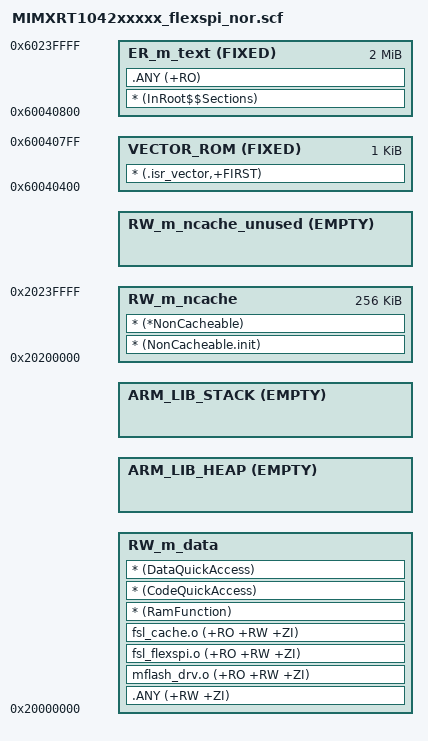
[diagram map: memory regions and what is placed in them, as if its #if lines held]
#!armclang --target=arm-arm-none-eabi -mcpu=cortex-m7 -E -x c
/*
** ###################################################################
**     Processors:          MIMXRT1042DFP6B
**                          MIMXRT1042XFP5B
**                          MIMXRT1042XJM5B
**
**     Compiler:            Keil ARM C/C++ Compiler
**     Reference manual:    IMXRT1040RM Rev.A, 09/2021
**     Version:             rev. 0.1, 2021-07-20
**     Build:               b211221
**
**     Abstract:
**         Linker file for the Keil ARM C/C++ Compiler
**
**     Copyright 2016 Freescale Semiconductor, Inc.
**     Copyright 2016-2021 NXP
**     All rights reserved.
**
**     SPDX-License-Identifier: BSD-3-Clause
**
**     http:                 www.nxp.com
**     mail:                 support@nxp.com
**
** ###################################################################
*/

/* Primary application image is up to 2 MB in size including headers and interrupt vectors */

#define m_interrupts_start             0x60040400
#define m_interrupts_size              0x00000400

#define m_text_start                   0x60040800
#define m_text_size                    0x001FF800

#define m_data_start                   0x20000000
#define m_data_size                    0x00020000

#define m_ncache_start                 0x20200000
#define m_ncache_size                  0x00040000


/* Sizes */
#if (defined(__stack_size__))
  #define Stack_Size                   __stack_size__
#else
  #define Stack_Size                   0x0400
#endif

#if (defined(__heap_size__))
  #define Heap_Size                    __heap_size__
#else
  #define Heap_Size                    0x0400
#endif

LR_m_text m_interrupts_start m_text_start+m_text_size-m_interrupts_start {   ; load region size_region
  VECTOR_ROM m_interrupts_start FIXED m_interrupts_size { ; load address = execution address
    * (.isr_vector,+FIRST)
  }
  ER_m_text m_text_start FIXED m_text_size { ; load address = execution address
    * (InRoot$$Sections)
    .ANY (+RO)
  }
  RW_m_data m_data_start m_data_size-Stack_Size-Heap_Size { ; RW data
    .ANY (+RW +ZI)

    /* Explicitly place flash operation functions in RAM. */
    mflash_drv.o (+RO +RW +ZI)
    fsl_flexspi.o (+RO +RW +ZI)
    fsl_cache.o (+RO +RW +ZI)

    * (RamFunction)
    * (CodeQuickAccess)
    * (DataQuickAccess)
  }
  ARM_LIB_HEAP +0 EMPTY Heap_Size {    ; Heap region growing up
  }
  ARM_LIB_STACK m_data_start+m_data_size EMPTY -Stack_Size { ; Stack region growing down
  }
  RW_m_ncache m_ncache_start m_ncache_size {
    * (NonCacheable.init)
    * (*NonCacheable)
  }
  RW_m_ncache_unused +0 EMPTY m_ncache_size-ImageLength(RW_m_ncache) { ; Empty region added for MPU configuration
  }
}
